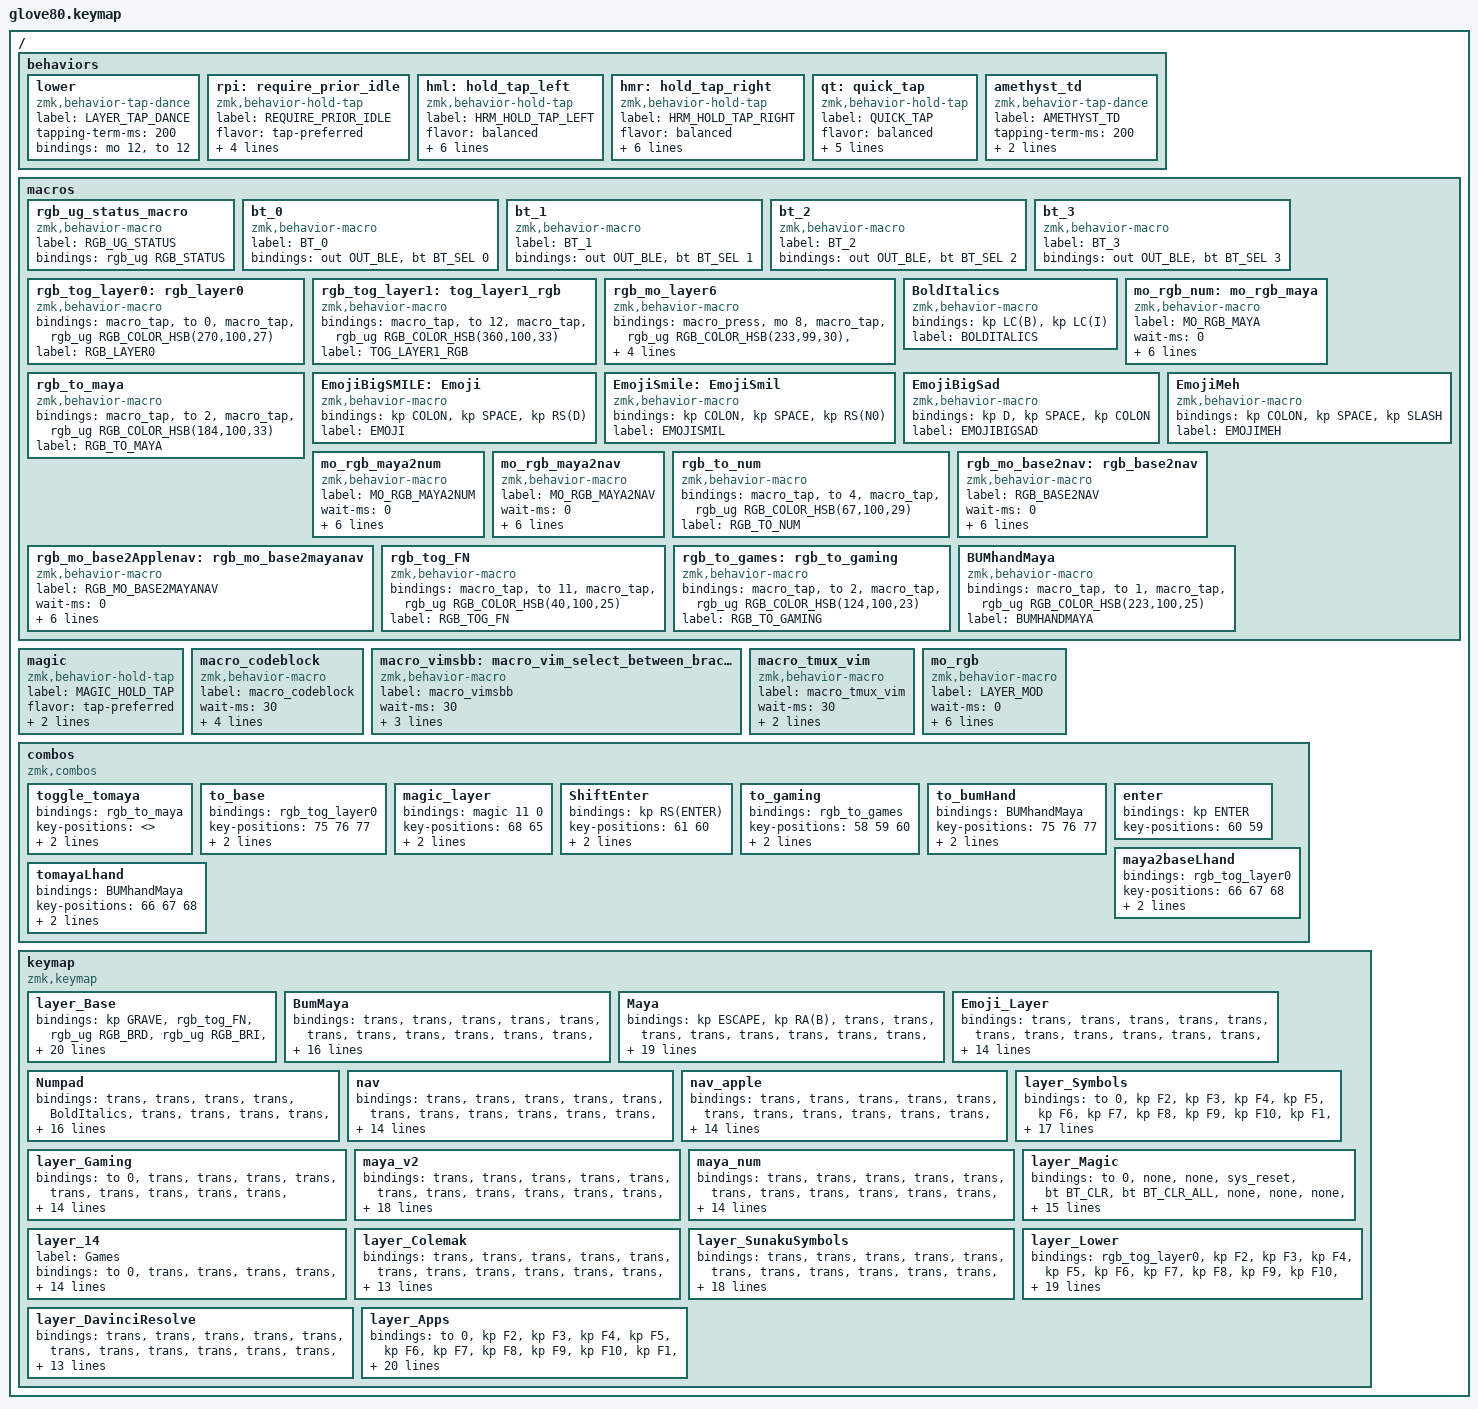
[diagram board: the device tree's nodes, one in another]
/*
 * Copyright (c) 2020 The ZMK Contributors
 * Copyright (c) 2023 Innaworks Development Limited, trading as MoErgo
 *
 * SPDX-License-Identifier: MIT
 */
/* THIS FILE WAS GENERATED BY GLOVE80 LAYOUT EDITOR
 *
 * This file was generated automatically. You may or may not want to
 * edit it directly.
 */
/* Include all behaviour includes needed */

#include <behaviors.dtsi>
#include <dt-bindings/zmk/bt.h>
#include <dt-bindings/zmk/keys.h>
#include <dt-bindings/zmk/outputs.h>
#include <dt-bindings/zmk/rgb.h>

/* Automatically generated layer name #define */

#define HYPER(keycode) LS(LC(LA(LG(keycode))))
#define MEH(keycode) LS(LC(LA(keycode)))

/* #define layers */

#define LAYER_Base 0
#define LAYER_Lower 1
#define LAYER_Colemak 2
#define LAYER_Symbols 3
#define LAYER_Magic 4
#define LAYER_Apps 5

/* #define for key positions */

#define POS_LH_T1 52
#define POS_LH_T2 53
#define POS_LH_T3 54
#define POS_LH_T4 69
#define POS_LH_T5 70
#define POS_LH_T6 71
#define POS_LH_C1R2 15
#define POS_LH_C1R3 27
#define POS_LH_C1R4 39
#define POS_LH_C1R5 51
#define POS_LH_C2R1 4
#define POS_LH_C2R2 14
#define POS_LH_C2R3 26
#define POS_LH_C2R4 38
#define POS_LH_C2R5 50
#define POS_LH_C2R6 68
#define POS_LH_C3R1 3
#define POS_LH_C3R2 13
#define POS_LH_C3R3 25
#define POS_LH_C3R4 37
#define POS_LH_C3R5 49
#define POS_LH_C3R6 67
#define POS_LH_C4R1 2
#define POS_LH_C4R2 12
#define POS_LH_C4R3 24
#define POS_LH_C4R4 36
#define POS_LH_C4R5 48
#define POS_LH_C4R6 66
#define POS_LH_C5R1 1
#define POS_LH_C5R2 11
#define POS_LH_C5R3 23
#define POS_LH_C5R4 35
#define POS_LH_C5R5 47
#define POS_LH_C5R6 65
#define POS_LH_C6R1 0
#define POS_LH_C6R2 10
#define POS_LH_C6R3 22
#define POS_LH_C6R4 34
#define POS_LH_C6R5 46
#define POS_LH_C6R6 64
#define POS_RH_T1 57
#define POS_RH_T2 56
#define POS_RH_T3 55
#define POS_RH_T4 74
#define POS_RH_T5 73
#define POS_RH_T6 72
#define POS_RH_C1R2 16
#define POS_RH_C1R3 28
#define POS_RH_C1R4 40
#define POS_RH_C1R5 58
#define POS_RH_C2R1 5
#define POS_RH_C2R2 17
#define POS_RH_C2R3 29
#define POS_RH_C2R4 41
#define POS_RH_C2R5 59
#define POS_RH_C2R6 75
#define POS_RH_C3R1 6
#define POS_RH_C3R2 18
#define POS_RH_C3R3 30
#define POS_RH_C3R4 42
#define POS_RH_C3R5 60
#define POS_RH_C3R6 76
#define POS_RH_C4R1 7
#define POS_RH_C4R2 19
#define POS_RH_C4R3 31
#define POS_RH_C4R4 43
#define POS_RH_C4R5 61
#define POS_RH_C4R6 77
#define POS_RH_C5R1 8
#define POS_RH_C5R2 20
#define POS_RH_C5R3 32
#define POS_RH_C5R4 44
#define POS_RH_C5R5 62
#define POS_RH_C5R6 78
#define POS_RH_C6R1 9
#define POS_RH_C6R2 21
#define POS_RH_C6R3 33
#define POS_RH_C6R4 45
#define POS_RH_C6R5 63
#define POS_RH_C6R6 79

// NOTE: I removed "C" (POS_LH_C3R4) and "D" (POS_LH_C3R5) from `KEYS_LEFT` so I can still do one-handed CTRL-C and CTRL-D

#define KEYS_LEFT POS_LH_C1R2 POS_LH_C1R3 POS_LH_C1R4 POS_LH_C1R5 POS_LH_C2R1 POS_LH_C2R2 POS_LH_C2R3 POS_LH_C2R4 POS_LH_C2R5 POS_LH_C2R6 POS_LH_C3R1 POS_LH_C3R2 POS_LH_C3R3 POS_LH_C3R6 POS_LH_C4R1 POS_LH_C4R2 POS_LH_C4R3 POS_LH_C4R4 POS_LH_C4R5 POS_LH_C4R6 POS_LH_C5R1 POS_LH_C5R2 POS_LH_C5R3 POS_LH_C5R4 POS_LH_C5R5 POS_LH_C5R6 POS_LH_C6R1 POS_LH_C6R2 POS_LH_C6R3 POS_LH_C6R4 POS_LH_C6R5 POS_LH_C6R6
#define KEYS_RIGHT POS_RH_C1R2 POS_RH_C1R3 POS_RH_C1R4 POS_RH_C1R5 POS_RH_C2R1 POS_RH_C2R2 POS_RH_C2R3 POS_RH_C2R4 POS_RH_C2R5 POS_RH_C2R6 POS_RH_C3R1 POS_RH_C3R2 POS_RH_C3R3 POS_RH_C3R4 POS_RH_C3R5 POS_RH_C3R6 POS_RH_C4R1 POS_RH_C4R2 POS_RH_C4R3 POS_RH_C4R4 POS_RH_C4R5 POS_RH_C4R6 POS_RH_C5R1 POS_RH_C5R2 POS_RH_C5R3 POS_RH_C5R4 POS_RH_C5R5 POS_RH_C5R6 POS_RH_C6R1 POS_RH_C6R2 POS_RH_C6R3 POS_RH_C6R4 POS_RH_C6R5 POS_RH_C6R6
#define THUMBS POS_RH_T1 POS_RH_T2 POS_RH_T3 POS_RH_T4 POS_RH_T5 POS_RH_T6 POS_LH_T1 POS_LH_T2 POS_LH_T3 POS_LH_T4 POS_LH_T5 POS_LH_T6

/ {
    /* Glove80 system behavior & macros */

    behaviors {
        // For the "layer" key, it'd nice to be able to use it as either a shift or a toggle.
        // Configure it as a tap dance, so the first tap (or hold) is a &mo and the second tap is a &to

        lower: lower {
            compatible = "zmk,behavior-tap-dance";
            label = "LAYER_TAP_DANCE";
            #binding-cells = <0>;
            tapping-term-ms = <200>;
            bindings = <&mo 12>, <&to 12>;
        };

        rpi: require_prior_idle {
            compatible = "zmk,behavior-hold-tap";
            label = "REQUIRE_PRIOR_IDLE";
            #binding-cells = <2>;
            flavor = "tap-preferred";
            tapping-term-ms = <175>;
            quick-tap-ms = <150>;
            require-prior-idle-ms = <125>;
            bindings = <&kp>, <&kp>;
        };

        hml: hold_tap_left {
            compatible = "zmk,behavior-hold-tap";
            label = "HRM_HOLD_TAP_LEFT";
            flavor = "balanced";
            tapping-term-ms = <280>;
            quick-tap-ms = <175>;
            require-prior-idle-ms = <150>;
            #binding-cells = <2>;
            bindings = <&kp>, <&kp>;

            hold-trigger-key-positions = <KEYS_RIGHT THUMBS>;
            hold-trigger-on-release;
        };

        hmr: hold_tap_right {
            compatible = "zmk,behavior-hold-tap";
            label = "HRM_HOLD_TAP_RIGHT";
            flavor = "balanced";
            tapping-term-ms = <280>;
            quick-tap-ms = <175>;
            require-prior-idle-ms = <150>;
            #binding-cells = <2>;
            bindings = <&kp>, <&kp>;

            hold-trigger-key-positions = <KEYS_LEFT THUMBS>;
            hold-trigger-on-release;
        };

        qt: quick_tap {
            compatible = "zmk,behavior-hold-tap";
            label = "QUICK_TAP";
            flavor = "balanced";
            tapping-term-ms = <200>;
            quick-tap-ms = <175>;
            require-prior-idle-ms = <150>;
            #binding-cells = <2>;
            bindings = <&kp>, <&kp>;

            hold-trigger-on-release;
        };

        amethyst_td: amethyst_td {
            compatible = "zmk,behavior-tap-dance";
            label = "AMETHYST_TD";
            #binding-cells = <0>;
            tapping-term-ms = <200>;
            bindings =
                <&kp LS(LEFT_ALT)>,
                <&kp LS(LA(LCTRL))>,
                <&kp LS(LA(LC(Z)))>;
        };
    };
};

/ {
    macros {
        rgb_ug_status_macro: rgb_ug_status_macro {
            label = "RGB_UG_STATUS";
            compatible = "zmk,behavior-macro";
            #binding-cells = <0>;
            bindings = <&rgb_ug RGB_STATUS>;
        };

        bt_0: bt_0 {
            label = "BT_0";
            compatible = "zmk,behavior-macro";
            #binding-cells = <0>;
            bindings = <&out OUT_BLE &bt BT_SEL 0>;
        };

        bt_1: bt_1 {
            label = "BT_1";
            compatible = "zmk,behavior-macro";
            #binding-cells = <0>;
            bindings = <&out OUT_BLE &bt BT_SEL 1>;
        };

        bt_2: bt_2 {
            label = "BT_2";
            compatible = "zmk,behavior-macro";
            #binding-cells = <0>;
            bindings = <&out OUT_BLE &bt BT_SEL 2>;
        };

        bt_3: bt_3 {
            label = "BT_3";
            compatible = "zmk,behavior-macro";
            #binding-cells = <0>;
            bindings = <&out OUT_BLE &bt BT_SEL 3>;
        };

        rgb_tog_layer0: rgb_layer0 {
            compatible = "zmk,behavior-macro";
            #binding-cells = <0>;
            bindings =
                <&macro_tap>,
                <&to 0>,
                <&macro_tap>,
                <&rgb_ug RGB_COLOR_HSB(270,100,27)>;

            label = "RGB_LAYER0";
        };

        rgb_tog_layer1: tog_layer1_rgb {
            compatible = "zmk,behavior-macro";
            #binding-cells = <0>;
            bindings =
                <&macro_tap>,
                <&to 12>,
                <&macro_tap>,
                <&rgb_ug RGB_COLOR_HSB(360,100,33)>;

            label = "TOG_LAYER1_RGB";
        };

        rgb_mo_layer6: rgb_mo_layer6 {
            compatible = "zmk,behavior-macro";
            #binding-cells = <0>;
            bindings =
                <&macro_press>,
                <&mo 8>,
                <&macro_tap>,
                <&rgb_ug RGB_COLOR_HSB(233,99,30)>,
                <&macro_pause_for_release>,
                <&macro_release>,
                <&mo 8>,
                <&macro_tap>,
                <&rgb_ug RGB_COLOR_HSB(357,100,30)>;

            label = "RGB_MO_LAYER6";
        };

        BoldItalics: BoldItalics {
            compatible = "zmk,behavior-macro";
            #binding-cells = <0>;
            bindings = <&kp LC(B) &kp LC(I)>;
            label = "BOLDITALICS";
        };

        mo_rgb_num: mo_rgb_maya {
            compatible = "zmk,behavior-macro";
            label = "MO_RGB_MAYA";
            wait-ms = <0>;
            tap-ms = <0>;
            #binding-cells = <0>;
            bindings =
                <&macro_press>,
                <&mo 4>,
                <&macro_tap>,
                <&rgb_ug RGB_COLOR_HSB(56,100,32)>,
                <&macro_pause_for_release>,
                <&macro_release>,
                <&mo 4>,
                <&macro_tap>,
                <&rgb_ug RGB_COLOR_HSB(265,100,27)>;
        };

        rgb_to_maya: rgb_to_maya {
            compatible = "zmk,behavior-macro";
            #binding-cells = <0>;
            bindings =
                <&macro_tap>,
                <&to 2>,
                <&macro_tap>,
                <&rgb_ug RGB_COLOR_HSB(184,100,33)>;

            label = "RGB_TO_MAYA";
        };

        EmojiBigSMILE: Emoji {
            compatible = "zmk,behavior-macro";
            #binding-cells = <0>;
            bindings = <&kp COLON &kp SPACE &kp RS(D)>;
            label = "EMOJI";
        };

        EmojiSmile: EmojiSmil {
            compatible = "zmk,behavior-macro";
            #binding-cells = <0>;
            bindings = <&kp COLON &kp SPACE &kp RS(N0)>;
            label = "EMOJISMIL";
        };

        EmojiBigSad: EmojiBigSad {
            compatible = "zmk,behavior-macro";
            #binding-cells = <0>;
            bindings = <&kp D &kp SPACE &kp COLON>;
            label = "EMOJIBIGSAD";
        };

        EmojiMeh: EmojiMeh {
            compatible = "zmk,behavior-macro";
            #binding-cells = <0>;
            bindings = <&kp COLON &kp SPACE &kp SLASH>;
            label = "EMOJIMEH";
        };

        mo_rgb_maya2num: mo_rgb_maya2num {
            compatible = "zmk,behavior-macro";
            label = "MO_RGB_MAYA2NUM";
            wait-ms = <0>;
            tap-ms = <0>;
            #binding-cells = <0>;
            bindings =
                <&macro_press>,
                <&mo 4>,
                <&macro_tap>,
                <&rgb_ug RGB_COLOR_HSB(56,100,32)>,
                <&macro_pause_for_release>,
                <&macro_release>,
                <&mo 4>,
                <&macro_tap>,
                <&rgb_ug RGB_COLOR_HSB(182,100,28)>;
        };

        mo_rgb_maya2nav: mo_rgb_maya2nav {
            compatible = "zmk,behavior-macro";
            label = "MO_RGB_MAYA2NAV";
            wait-ms = <0>;
            tap-ms = <0>;
            #binding-cells = <0>;
            bindings =
                <&macro_press>,
                <&mo 5>,
                <&macro_tap>,
                <&rgb_ug RGB_COLOR_HSB(360,100,21)>,
                <&macro_pause_for_release>,
                <&macro_release>,
                <&mo 5>,
                <&macro_tap>,
                <&rgb_ug RGB_COLOR_HSB(182,100,28)>;
        };

        rgb_to_num: rgb_to_num {
            compatible = "zmk,behavior-macro";
            #binding-cells = <0>;
            bindings =
                <&macro_tap>,
                <&to 4>,
                <&macro_tap>,
                <&rgb_ug RGB_COLOR_HSB(67,100,29)>;

            label = "RGB_TO_NUM";
        };

        rgb_mo_base2nav: rgb_base2nav {
            compatible = "zmk,behavior-macro";
            label = "RGB_BASE2NAV";
            wait-ms = <0>;
            tap-ms = <0>;
            #binding-cells = <0>;
            bindings =
                <&macro_press>,
                <&mo 5>,
                <&macro_tap>,
                <&rgb_ug RGB_COLOR_HSB(360,100,23)>,
                <&macro_pause_for_release>,
                <&macro_release>,
                <&mo 5>,
                <&macro_tap>,
                <&rgb_ug RGB_COLOR_HSB(265,100,27)>;
        };

        rgb_mo_base2Applenav: rgb_mo_base2mayanav {
            compatible = "zmk,behavior-macro";
            label = "RGB_MO_BASE2MAYANAV";
            wait-ms = <0>;
            tap-ms = <0>;
            #binding-cells = <0>;
            bindings =
                <&macro_press>,
                <&mo 6>,
                <&macro_tap>,
                <&rgb_ug RGB_COLOR_HSB(299,100,31)>,
                <&macro_pause_for_release>,
                <&macro_release>,
                <&mo 6>,
                <&macro_tap>,
                <&rgb_ug RGB_COLOR_HSB(265,100,27)>;
        };

        rgb_tog_FN: rgb_tog_FN {
            compatible = "zmk,behavior-macro";
            #binding-cells = <0>;
            bindings =
                <&macro_tap>,
                <&to 11>,
                <&macro_tap>,
                <&rgb_ug RGB_COLOR_HSB(40,100,25)>;

            label = "RGB_TOG_FN";
        };

        rgb_to_games: rgb_to_gaming {
            compatible = "zmk,behavior-macro";
            #binding-cells = <0>;
            bindings =
                <&macro_tap>,
                <&to 2>,
                <&macro_tap>,
                <&rgb_ug RGB_COLOR_HSB(124,100,23)>;

            label = "RGB_TO_GAMING";
        };

        BUMhandMaya: BUMhandMaya {
            compatible = "zmk,behavior-macro";
            #binding-cells = <0>;
            bindings =
                <&macro_tap>,
                <&to 1>,
                <&macro_tap>,
                <&rgb_ug RGB_COLOR_HSB(223,100,25)>;

            label = "BUMHANDMAYA";
        };
    };
};

/ {
    magic: magic {
        compatible = "zmk,behavior-hold-tap";
        label = "MAGIC_HOLD_TAP";
        #binding-cells = <2>;
        flavor = "tap-preferred";
        tapping-term-ms = <200>;
        bindings = <&mo>, <&rgb_ug_status_macro>;
    };
};

/* Custom Defined Behaviors */

/ {
    macro_codeblock: macro_codeblock {
        compatible = "zmk,behavior-macro";
        label = "macro_codeblock";
        #binding-cells = <0>;
        wait-ms = <30>;
        tap-ms = <40>;
        bindings = <&kp GRAVE &kp GRAVE &kp GRAVE &kp LS(ENTER) &kp GRAVE &kp GRAVE &kp GRAVE &kp UP &kp LS(ENTER)>;
    };

    macro_vimsbb: macro_vim_select_between_brackets {
        compatible = "zmk,behavior-macro";
        label = "macro_vimsbb";
        #binding-cells = <0>;
        wait-ms = <30>;
        tap-ms = <40>;
        bindings = <&kp LS(N4) &kp LS(V) &kp PERCENT &kp LS(N4)>;
    };

    macro_tmux_vim: macro_tmux_vim {
        compatible = "zmk,behavior-macro";
        label = "macro_tmux_vim";
        #binding-cells = <0>;
        wait-ms = <30>;
        tap-ms = <40>;
        bindings = <&kp LG(S) &kp LBKT>;
    };

    mo_rgb: mo_rgb {
        label = "LAYER_MOD";
        compatible = "zmk,behavior-macro";
        wait-ms = <0>;
        tap-ms = <0>;
        #binding-cells = <0>;
        bindings =
            <&macro_press>,
            <&mo 11>,
            <&macro_tap>,
            <&rgb_ug RGB_COLOR_HSB(128,100,100)>,
            <&macro_pause_for_release>,
            <&macro_release>,
            <&mo 11>,
            <&macro_tap>,
            <&rgb_ug RGB_COLOR_HSB(300,100,50)>;
    };
};

/ {
    behaviors {
    };

    combos {
        compatible = "zmk,combos";

        toggle_tomaya {
            bindings = <&rgb_to_maya>;
            key-positions = <>;
            layers = <0>;
            require-prior-idle-ms = <150>;
        };

        to_base {
            bindings = <&rgb_tog_layer0>;
            key-positions = <75 76 77>;
            require-prior-idle-ms = <150>;
            layers = <4 2 8 12 1>;
        };

        magic_layer {
            bindings = <&magic 11 0>;
            key-positions = <68 65>;
            layers = <0 12>;
            require-prior-idle-ms = <200>;
        };

        ShiftEnter {
            bindings = <&kp RS(ENTER)>;
            key-positions = <61 60>;
            require-prior-idle-ms = <150>;
            layers = <0 4 2>;
        };

        to_gaming {
            bindings = <&rgb_to_games>;
            key-positions = <58 59 60>;
            require-prior-idle-ms = <150>;
            layers = <2 0 4 7 8 12>;
        };

        to_bumHand {
            bindings = <&BUMhandMaya>;
            key-positions = <75 76 77>;
            require-prior-idle-ms = <150>;
            layers = <4 2 8 0>;
        };

        enter {
            bindings = <&kp ENTER>;
            key-positions = <60 59>;
        };

        maya2baseLhand {
            bindings = <&rgb_tog_layer0>;
            key-positions = <66 67 68>;
            require-prior-idle-ms = <150>;
            layers = <4 2 8 12 1>;
        };

        tomayaLhand {
            bindings = <&BUMhandMaya>;
            key-positions = <66 67 68>;
            require-prior-idle-ms = <150>;
            layers = <4 2 8 0>;
        };
    };

    keymap {
        compatible = "zmk,keymap";

        layer_Base {
            bindings = <
&kp GRAVE         &rgb_tog_FN  &rgb_ug RGB_BRD      &rgb_ug RGB_BRI  &kp BACKSLASH                                                                                                                    &kp LEFT_BRACKET   &kp RIGHT_BRACKET  &kp F8                &kp PRINTSCREEN  &kp F11
&kp EQUAL         &kp N1       &kp N2               &kp N3           &kp N4             &kp N5                                                                                                &kp N6  &kp N7             &kp N8             &kp N9                &kp N0           &kp MINUS
&kp ESCAPE        &kp Q        &kp W                &kp E            &kp R              &kp T                                                                                                 &kp Y   &kp U              &kp I              &kp O                 &kp P            &hmr RIGHT_WIN DEL
&kp TAB           &kp A        &hml LEFT_CONTROL S  &hml LEFT_WIN D  &hml LEFT_SHIFT F  &kp G                                                                                                 &kp H   &hmr LEFT_SHIFT J  &hmr LEFT_WIN K    &hmr RIGHT_CONTROL L  &lt 3 SEMICOLON  &kp SQT
&kp LEFT_CONTROL  &kp Z        &kp X                &kp C            &kp V              &kp B   &kp RIGHT_ALT  &mo_rgb_num       &magic 11 0  &kp LC(Y)  &kp ENTER      &kp LEFT_SHIFT        &kp B   &kp N              &kp M              &kp COMMA             &kp DOT          &kp FSLH
&rgb_mo_base2nav  &kp LEFT     &kp A                &kp A            &kp B                      &kp RSHFT      &kp LEFT_CONTROL  &kp ENTER    &kp LC(Z)  &kp BACKSPACE  &qt LEFT_SHIFT SPACE          &kp LEFT           &kp UP_ARROW       &kp DOWN              &kp RIGHT        &kp RIGHT
            >;
        };

        BumMaya {
            bindings = <
&trans            &trans            &trans  &trans  &trans                                                                                                             &trans    &trans        &trans          &trans           &trans
&trans            &trans            &trans  &trans  &trans     &trans                                                                                      &kp RS(N8)  &kp N7    &kp N8        &kp N9          &kp BACKSPACE    &kp PRINTSCREEN
&trans            &trans            &trans  &trans  &trans     &trans                                                                                      &kp FSLH    &kp N4    &kp N5        &kp N6          &BoldItalics     &trans
&trans            &trans            &trans  &trans  &trans     &trans                                                                                      &kp EQUAL   &kp N1    &kp N2        &kp N3          &kp LC(A)        &kp RC(C)
&trans            &mo_rgb_maya2num  &trans  &trans  &trans     &trans  &kp LCTRL  &kp LC(Z)       &kp LC(Y)           &kp RC(A)  &kp RC(C)      &kp RC(V)  &kp MINUS   &kp DOT   &kp N0        &kp ENTER       &kp RC(X)        &kp RC(V)
&mo_rgb_maya2nav  &kp LEFT_CONTROL  &trans  &trans  &kp RA(W)          &kp RALT   &kp LEFT_SHIFT  &kp RA(LEFT_SHIFT)  &kp ENTER  &kp BACKSPACE  &kp LSHFT              &kp LEFT  &kp UP_ARROW  &kp DOWN_ARROW  &kp RIGHT_ARROW  &trans
            >;
        };

        Maya {
            bindings = <
&kp ESCAPE        &kp RA(B)          &trans               &trans               &trans                                                                                                                &trans    &trans        &trans          &trans           &trans
&kp DEL           &kp RC(D)          &trans               &kp LC(S)            &kp LC(RA(S))             &kp F8                                                                          &kp RS(N8)  &kp N7    &kp N8        &kp N9          &kp BACKSPACE    &kp PRINTSCREEN
&kp A             &kp F              &mt RA(N1) NUMBER_1  &mt N2 RA(NUMBER_2)  &mt N3 RA(NUMBER_4)       &kp H                                                                           &kp FSLH    &kp N4    &kp N5        &kp N6          &kp DEL          &trans
&kp LBKT          &kp RIGHT_BRACKET  &hml RA(W) W         &kp E                &hml LEFT_CONTROL R       &kp S                                                                           &kp EQUAL   &kp N1    &kp N2        &kp N3          &kp LBKT         &kp RBKT
&kp BSLH          &mo_rgb_maya2num   &kp X                &kp C                &kp LEFT_SHIFT            &kp EQUAL  &kp X     &kp C      &trans     &kp RC(A)  &kp RC(C)      &kp RC(V)  &kp MINUS   &kp DOT   &kp N0        &kp ENTER       &kp A            &kp F
&mo_rgb_maya2nav  &kp LEFT_CONTROL   &kp RA(V)            &kp SPACE            &qt RA(LEFT_SHIFT) MINUS             &kp RALT  &kp RC(Z)  &kp LC(Y)  &kp ENTER  &kp BACKSPACE  &kp LSHFT              &kp LEFT  &kp UP_ARROW  &kp DOWN_ARROW  &kp RIGHT_ARROW  &trans
            >;
        };

        Emoji_Layer {
            bindings = <
&trans  &trans  &trans  &trans  &trans                                                                  &trans        &trans            &trans             &trans  &trans
&trans  &trans  &trans  &trans  &trans  &trans                                                  &trans  &trans        &trans            &trans             &trans  &trans
&trans  &trans  &trans  &trans  &trans  &trans                                                  &trans  &trans        &kp LEFT_BRACKET  &kp RIGHT_BRACKET  &trans  &trans
&trans  &trans  &trans  &trans  &trans  &trans                                                  &trans  &kp EXCL      &EmojiSmile       &EmojiBigSMILE     &trans  &trans
&trans  &trans  &trans  &trans  &trans  &trans  &trans  &trans  &trans  &trans  &trans  &trans  &trans  &kp QUESTION  &EmojiMeh         &EmojiBigSad       &trans  &kp PAGE_UP
&trans  &trans  &trans  &trans  &trans          &trans  &trans  &trans  &trans  &trans  &trans          &trans        &trans            &trans             &trans  &kp PAGE_DOWN
            >;
        };

        Numpad {
            bindings = <
&trans           &trans          &trans        &trans          &BoldItalics                                                                                                     &trans          &trans        &trans          &trans           &trans
&trans           &kp BSPC        &kp N7        &kp N8          &kp N9           &kp RS(N8)                                                                          &kp RS(N8)  &kp N7          &kp N8        &kp N9          &kp BSPC         &trans
&trans           &kp DEL         &kp N4        &kp N5          &kp N6           &kp FSLH                                                                            &kp FSLH    &kp N4          &kp N5        &kp N6          &kp DELETE       &trans
&trans           &trans          &kp N1        &kp N2          &kp N3           &kp EQUAL                                                                           &kp EQUAL   &kp N1          &kp N2        &kp N3          &trans           &trans
&trans           &trans          &kp ENTER     &kp N0          &kp PERIOD       &kp MINUS   &kp LC(A)  &kp LC(C)  &kp LC(V)  &kp RC(A)        &kp RC(C)  &kp RC(V)  &kp MINUS   &kp DOT         &kp N0        &kp ENTER       &trans           &trans
&rgb_tog_layer0  &kp LEFT_ARROW  &kp UP_ARROW  &kp DOWN_ARROW  &kp RIGHT_ARROW              &kp RSHFT  &kp BSPC   &kp ENTER  &rgb_tog_layer0  &kp BSPC   &kp RSHFT              &kp LEFT_ARROW  &kp UP_ARROW  &kp DOWN_ARROW  &kp RIGHT_ARROW  &trans
            >;
        };

        nav {
            bindings = <
&trans  &trans     &trans          &trans          &trans                                                                                                 &trans  &trans  &trans  &trans  &trans
&trans  &trans     &trans          &trans          &trans           &trans                                                                        &trans  &trans  &trans  &trans  &trans  &trans
&trans  &trans     &trans          &trans          &trans           &trans                                                                        &trans  &trans  &trans  &trans  &trans  &trans
&trans  &kp LC(Y)  &kp LC(I)       &kp UP_ARROW    &kp LC(B)        &kp LC(X)                                                                     &trans  &trans  &trans  &trans  &trans  &trans
&trans  &kp RC(Z)  &kp LEFT_ARROW  &kp DOWN_ARROW  &kp RIGHT_ARROW  &BoldItalics  &trans            &trans        &trans  &trans  &trans  &trans  &trans  &trans  &trans  &trans  &trans  &trans
&trans  &trans     &kp RC(A)       &kp LC(C)       &kp LC(V)                      &kp LEFT_CONTROL  &kp LEFT_WIN  &trans  &trans  &trans  &trans          &trans  &trans  &trans  &trans  &trans
            >;
        };

        nav_apple {
            bindings = <
&trans  &trans     &trans          &trans          &trans                                                                                               &trans  &trans  &trans  &trans  &trans
&trans  &trans     &trans          &trans          &trans           &trans                                                                      &trans  &trans  &trans  &trans  &trans  &trans
&trans  &trans     &trans          &trans          &trans           &trans                                                                      &trans  &trans  &trans  &trans  &trans  &trans
&trans  &kp LG(Y)  &kp LG(X)       &kp UP_ARROW    &kp I            &kp LG(A)                                                                   &trans  &trans  &trans  &trans  &trans  &trans
&trans  &kp LG(Z)  &kp LEFT_ARROW  &kp DOWN_ARROW  &kp RIGHT_ARROW  &kp LG(B)  &trans         &trans     &trans         &trans  &trans  &trans  &trans  &trans  &trans  &trans  &trans  &trans
&trans  &trans     &kp LG(A)       &kp LG(C)       &kp LG(V)                   &kp BACKSPACE  &kp ENTER  &kp LS(ENTER)  &trans  &trans  &trans          &trans  &trans  &trans  &trans  &trans
            >;
        };

        layer_Symbols {
            bindings = <
&to 0            &kp F2           &kp F3            &kp F4      &kp F5                                                                                                        &kp F6     &kp F7            &kp F8            &kp F9        &kp F10
&kp F1           &kp C_PREVIOUS   &kp C_PLAY_PAUSE  &kp C_NEXT  &kp C_VOLUME_DOWN  &kp C_VOLUME_UP                                                             &kp C_MUTE     &trans     &trans            &trans            &trans        &kp F11
&kp TAB          &macro_tmux_vim  &kp AT_SIGN       &kp LBRC    &kp RBRC           &macro_vimsbb                                                               &kp LS(MINUS)  &kp PLUS   &kp ASTERISK      &kp EXCLAMATION   &trans        &kp F12
&trans           &kp POUND        &kp DOLLAR        &kp LPAR    &kp RPAR           &kp TAB                                                                     &kp MINUS      &kp EQUAL  &kp GREATER_THAN  &kp PIPE          &kp TILDE     &kp FSLH
&kp DELETE       &kp PERCENT      &kp CARET         &kp LBKT    &kp RBKT           &kp GRAVE        &trans  &trans  &trans  &macro_codeblock  &trans  &trans   &kp AMPERSAND  &kp COLON  &kp LESS_THAN     &kp GREATER_THAN  &kp QUESTION  &kp PAGE_UP
&rgb_tog_layer0  &trans           &trans            &trans      &kp LS(ENTER)                       &trans  &trans  &trans  &kp LS(TAB)       &trans  &kp ESC                 &trans     &trans            &trans            &trans        &kp PG_DN
            >;
        };

        layer_Gaming {
            bindings = <
&to 0       &trans          &trans     &trans     &trans                                                                                     &trans  &trans  &trans  &trans    &trans
&kp ESCAPE  &trans          &trans     &trans     &trans        &trans                                                             &trans    &trans  &trans  &trans  &trans    &trans
&kp TAB     &kp T           &kp Q      &kp W      &kp E         &kp R                                                              &trans    &trans  &trans  &trans  &trans    &trans
&kp G       &kp LEFT_SHIFT  &kp A      &kp S      &kp D         &kp F                                                              &kp RBKT  &kp J   &kp K   &kp L   &kp SEMI  &trans
&kp B       &kp LCTRL       &kp Z      &kp X      &kp C         &kp V   &kp LEFT_SHIFT  &trans     &trans  &trans  &trans  &trans  &trans    &trans  &trans  &trans  &trans    &kp PG_UP
&kp LCTRL   &kp LEFT_ALT    &kp PG_DN  &kp PG_UP  &kp LEFT_GUI          &kp SPACE       &kp ENTER  &trans  &trans  &trans  &trans            &trans  &trans  &trans  &trans    &kp PG_DN
            >;

            label = "GAMING";
        };

        maya_v2 {
            bindings = <
&trans            &trans            &trans               &trans               &trans                                                                                                           &trans    &trans        &trans          &trans           &trans
&trans            &trans            &trans               &trans               &trans               &kp F8                                                                          &kp RS(N8)  &kp N7    &kp N8        &kp N9          &kp BACKSPACE    &trans
&trans            &trans            &mt RA(N1) NUMBER_1  &mt N2 RA(NUMBER_2)  &mt N3 RA(NUMBER_4)  &trans                                                                          &kp FSLH    &kp N4    &kp N5        &kp N6          &kp DEL          &trans
&trans            &mo_rgb_maya2num  &kp W                &kp E                &kp R                &kp S                                                                           &kp EQUAL   &kp N1    &kp N2        &kp N3          &kp LBKT         &kp RBKT
&trans            &mo_rgb_maya2nav  &qt A LEFT_BRACKET   &qt F RIGHT_BRACKET  &kp LEFT_SHIFT       &kp EQUAL  &kp X     &kp C      &trans     &kp RC(A)  &kp RC(C)      &kp RC(V)  &kp MINUS   &kp DOT   &kp N0        &kp ENTER       &kp A            &kp F
&kp LEFT_CONTROL  &mo_rgb_maya2nav  &kp SPACE            &kp RA(V)            &kp MINUS                       &kp RALT  &kp RC(Z)  &kp LC(Y)  &kp SPACE  &kp BACKSPACE  &kp LSHFT              &kp LEFT  &kp UP_ARROW  &kp DOWN_ARROW  &kp RIGHT_ARROW  &trans
            >;
        };

        maya_num {
            bindings = <
&trans  &trans    &trans     &trans  &trans                                                                                             &trans   &trans  &trans     &trans    &trans
&trans  &trans    &trans     &trans  &trans   &kp RS(N8)                                                                    &kp RS(N8)  &trans   &trans  &trans     &trans    &trans
&trans  &kp BSPC  &kp N7     &kp N8  &kp N9   &kp FSLH                                                                      &kp FSLH    &kp N7   &kp N8  &kp N9     &kp BSPC  &trans
&trans  &kp DEL   &kp N4     &kp N5  &kp N6   &kp EQUAL                                                                     &kp EQUAL   &kp N4   &kp N5  &kp N6     &trans    &trans
&trans  &trans    &kp N1     &kp N2  &kp N3   &kp MINUS   &kp LC(A)  &kp LC(C)  &kp LC(V)  &kp RC(A)  &kp RC(C)  &kp RC(V)  &kp MINUS   &kp N1   &kp N2  &kp N3     &trans    &trans
&trans  &trans    &kp ENTER  &kp N0  &kp DOT              &kp RSHFT  &kp ENTER  &kp BSPC   &kp DEL    &kp ENTER  &kp RSHFT              &kp DOT  &kp N0  &kp ENTER  &trans    &trans
            >;
        };

        layer_Magic {
            bindings = <
&to 0        &none            &none            &sys_reset       &bt BT_CLR                                                                                         &bt BT_CLR_ALL   &none  &none  &none  &sys_reset
&none        &none            &none            &none            &none            &none                                                             &none           &none            &none  &none  &none  &none
&none        &rgb_ug RGB_SPI  &rgb_ug RGB_SAI  &rgb_ug RGB_HUI  &rgb_ug RGB_BRI  &rgb_ug RGB_TOG                                                   &rgb_ug RGB_ON  &rgb_ug RGB_OFF  &none  &none  &none  &none
&none        &rgb_ug RGB_SPD  &rgb_ug RGB_SAD  &rgb_ug RGB_HUD  &rgb_ug RGB_BRD  &rgb_ug RGB_EFF                                                   &none           &none            &none  &none  &none  &none
&bootloader  &none            &none            &none            &none            &bootloader      &bt_2  &bt_3  &none         &none  &none  &none  &bootloader     &none            &none  &none  &none  &bootloader
&none        &none            &none            &none            &none                             &bt_0  &bt_1  &out OUT_USB  &none  &none  &none                  &none            &none  &none  &none  &none
            >;
        };

        layer_14 {
            label = "Games";
            bindings = <
&to 0       &trans          &trans     &trans     &trans                                                                                           &trans  &trans  &trans  &trans    &trans
&kp ESCAPE  &trans          &trans     &trans     &trans        &trans                                                                   &trans    &trans  &trans  &trans  &trans    &trans
&kp TAB     &kp T           &kp Q      &kp W      &kp E         &kp R                                                                    &trans    &trans  &trans  &trans  &trans    &trans
&kp G       &kp LEFT_SHIFT  &kp A      &kp S      &kp D         &kp F                                                                    &kp RBKT  &kp J   &kp K   &kp L   &kp SEMI  &trans
&kp B       &kp LCTRL       &kp Z      &kp X      &kp C         &kp V   &kp LEFT_SHIFT  &trans     &trans        &trans  &trans  &trans  &trans    &trans  &trans  &trans  &trans    &kp PG_UP
&kp LCTRL   &kp LEFT_ALT    &kp PG_DN  &kp PG_UP  &kp LEFT_GUI          &kp SPACE       &kp ENTER  &kp LEFT_WIN  &trans  &trans  &trans            &trans  &trans  &trans  &trans    &kp PG_DN
            >;
        };

        layer_Colemak {
            bindings = <
&trans  &trans       &trans           &trans           &trans                                                                  &trans  &trans            &trans            &trans       &trans
&trans  &trans       &trans           &trans           &trans  &trans                                                  &trans  &trans  &trans            &trans            &trans       &trans
&trans  &kp Q        &kp W            &kp F            &kp P   &kp G                                                   &kp J   &kp L   &kp U             &kp Y             &kp SEMI     &trans
&trans  &qt LCTRL A  &hml LEFT_ALT R  &hml LEFT_GUI S  &kp T   &kp D                                                   &kp H   &kp N   &hmr RIGHT_GUI E  &hmr I RIGHT_ALT  &qt RCTRL O  &trans
&trans  &kp Z        &kp X            &kp C            &kp V   &kp B   &trans  &trans  &trans  &trans  &trans  &trans  &kp K   &kp M   &trans            &trans            &kp A        &trans
&trans  &trans       &trans           &trans           &trans          &trans  &trans  &trans  &trans  &trans  &trans          &trans  &trans            &trans            &trans       &trans
            >;
        };

        layer_SunakuSymbols {
            bindings = <
&trans         &trans          &trans                &trans                 &trans                                                                                          &trans          &trans       &trans        &trans        &trans
&trans         &kp GRAVE       &kp LS(LPAR)          &kp LS(RPAR)           &kp SEMI         &kp COMMA                                                            &trans    &trans          &trans       &trans        &trans        &trans
&kp LS(EXCL)   &kp LEFT_BRACE  &kp LEFT_PARENTHESIS  &kp RIGHT_PARENTHESIS  &kp RIGHT_BRACE  &kp QUESTION                                                         &kp SEMI  &kp LEFT_SHIFT  &kp LCTRL    &kp LEFT_ALT  &kp LEFT_GUI  &trans
&kp LS(POUND)  &kp LS(CARET)   &kp MINUS             &kp LS(UNDER)          &kp LS(DLLR)     &kp LS(STAR)                                                         &kp DOT   &kp BSPC        &kp TAB      &kp SPACE     &kp RET       &trans
&kp LS(TILDE)  &kp LS(LT)      &kp LS(PIPE)          &kp EQUAL              &kp LS(GT)       &kp FSLH      &trans  &trans  &trans  &kp BSLH       &trans  &trans  &kp FSLH  &kp DEL         &kp LS(TAB)  &trans        &trans        &trans
&kp LS(AT)     &kp LS(AMPS)    &kp LBKT              &kp RBKT               &kp LS(PLUS)                   &trans  &trans  &trans  &kp LS(PRCNT)  &trans  &trans            &kp LS(LPAR)    &kp LBKT     &kp RBKT      &kp LS(RPAR)  &trans
            >;
        };

        layer_Lower {
            bindings = <
&rgb_tog_layer0  &kp F2    &kp F3                    &kp F4            &kp F5                                                                                                                            &kp F6      &kp F7        &kp F8        &kp F9           &kp F10
&kp F1           &kp O     &kp C_PREVIOUS            &kp C_PLAY_PAUSE  &kp C_NEXT                 &kp T                                                                           &kp LEFT_PARENTHESIS   &kp KP_NUM  &kp KP_EQUAL  &kp KP_SLASH  &kp KP_MULTIPLY  &kp F11
&kp D            &kp N     &kp LS(LG(L))             &kp LG(LA(L))     &kp LA(Y)                  &kp LA(X)                                                                       &kp RIGHT_PARENTHESIS  &kp KP_N7   &kp KP_N8     &kp KP_N9     &kp KP_MINUS     &kp F12
&kp I            &kp A     &kp LS(LG(LEFT_BRACKET))  &kp LG(B)         &kp LS(LG(RIGHT_BRACKET))  &kp LS(BACKSPACE)                                                               &kp PERCENT            &kp KP_N4   &kp KP_N5     &kp KP_N6     &kp KP_PLUS      &kp K_MUTE
&kp LSHFT        &kp Z     &kp J                     &kp SPACE         &kp L                      &kp BACKSPACE      &trans  &trans  &trans           &to 13  &trans  &caps_word  &kp COMMA              &kp KP_N1   &kp KP_N2     &kp KP_N3     &kp KP_ENTER     &kp C_VOLUME_UP
&kp LCTRL        &kp LALT  &kp I                     &kp O             &trans                                        &trans  &trans  &rgb_tog_layer0  &to 8   &trans  &trans                             &kp KP_N0   &kp KP_N0     &kp KP_DOT    &kp KP_ENTER     &kp C_VOL_DN
            >;
        };

        layer_DavinciResolve {
            bindings = <
&trans  &trans  &trans  &trans  &trans                                                                  &trans  &trans  &trans  &trans  &trans
&trans  &trans  &trans  &trans  &trans  &trans                                                  &trans  &trans  &trans  &trans  &trans  &trans
&trans  &trans  &trans  &trans  &trans  &trans                                                  &trans  &trans  &trans  &trans  &trans  &trans
&trans  &trans  &trans  &trans  &trans  &trans                                                  &trans  &trans  &trans  &trans  &trans  &trans
&trans  &trans  &trans  &trans  &trans  &trans  &trans  &trans  &trans  &trans  &trans  &trans  &trans  &trans  &trans  &trans  &trans  &trans
&trans  &trans  &trans  &trans  &trans          &trans  &trans  &trans  &trans  &trans  &trans          &trans  &trans  &trans  &trans  &trans
            >;

            label = "DAVINCI_RESOLVE";
        };

        layer_Apps {
            bindings = <
&to 0   &kp F2                 &kp F3                 &kp F4                 &kp F5                                                                                                         &kp F6                 &kp F7                 &kp F8                 &kp F9                 &kp F10
&kp F1  &none                  &none                  &none                  &none                  &none                                                            &none                  &none                  &none                  &none                  &none                  &kp F11
&none   &kp LG(LS(LC(LA(Q))))  &kp LG(LS(LC(LA(W))))  &kp LG(LS(LC(LA(E))))  &kp LG(LS(LC(LA(R))))  &kp LG(LS(LC(LA(T))))                                            &kp LG(LS(LC(LA(Y))))  &kp LG(LS(LC(LA(U))))  &kp LG(LS(LC(LA(I))))  &kp LG(LS(LC(LA(O))))  &kp LG(LS(LC(LA(P))))  &kp F12
&none   &kp LG(LS(LC(LA(A))))  &kp LG(LS(LC(LA(S))))  &kp LG(LS(LC(LA(D))))  &kp LG(LS(LC(LA(F))))  &kp LG(LS(LC(LA(G))))                                            &kp LG(LS(LC(LA(H))))  &kp LG(LS(LC(LA(J))))  &kp LG(LS(LC(LA(K))))  &kp LG(LS(LC(LA(L))))  &none                  &none
&none   &kp LG(LS(LC(LA(Z))))  &kp LG(LS(LC(LA(X))))  &kp LG(LS(LC(LA(C))))  &kp LG(LS(LC(LA(V))))  &kp LG(LS(LC(LA(B))))  &none  &none  &none  &none  &none  &none  &kp LG(LS(LC(LA(N))))  &kp LG(LS(LC(LA(M))))  &none                  &none                  &none                  &none
&none   &none                  &none                  &none                  &none                                         &none  &none  &none  &none  &none  &none                         &none                  &none                  &none                  &none                  &to 8
            >;
        };
    };
};
